# f29h85x_dev_cfg_regs register map
Vendor: Texas Instruments
Peripheral module from a debugger description file (folder HSM).
Registers are 32-bit, read-write, no defined reset value unless marked. A register's access mark holds for its fields unless they carry their own. Offsets are as the file gives them; lines under a group give offsets from that group; [hi:lo] are bit positions; {n}, {i} and the like mark numbered series; 'fields as' and 'values as' point back to an identical list; <NAME> marks a mode.

## DEV_CFG_REGS — DEV CFG Registers
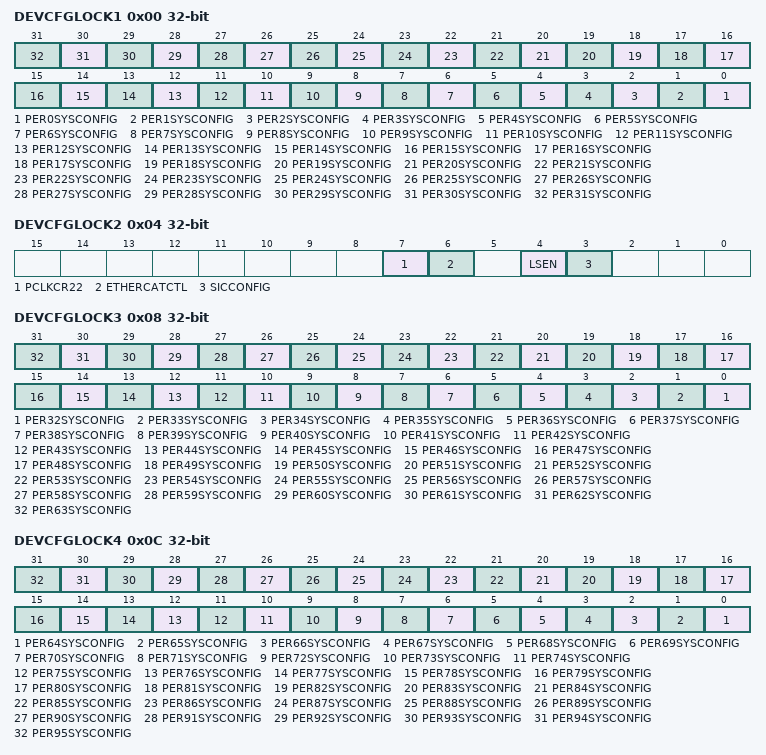
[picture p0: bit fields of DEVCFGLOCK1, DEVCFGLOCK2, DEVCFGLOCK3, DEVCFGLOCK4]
0x00 DEVCFGLOCK1 — Lock bit for PERxSYSCONFIG0-31 registers
  [n] PER{n}SYSCONFIG (n=0..31) — Lock bit for PER{n}SYSCONFIG register
0x04 DEVCFGLOCK2 — Lock bit for DEVCFG registers
  [7] PCLKCR22 — Lock for PCLKCR22
  [6] ETHERCATCTL — Lock for ETHERCATCTL
  [4] LSEN — Lock for LSEN
  [3] SICCONFIG — Lock for SICCONFIG
0x08 DEVCFGLOCK3 — Lock bit for PERxSYSCONFIG32-63 registers
  [n-32] PER{n}SYSCONFIG (n=32..63) — Lock bit for PER{n}SYSCONFIG register
0x0C DEVCFGLOCK4 — Lock bit for PERxSYSCONFIG64-95 registers
  [n-64] PER{n}SYSCONFIG (n=64..95) — Lock bit for PER{n}SYSCONFIG register
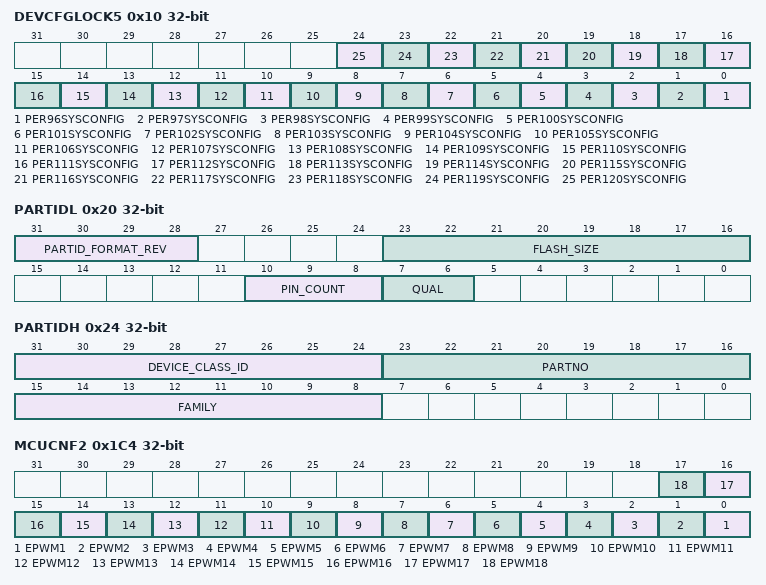
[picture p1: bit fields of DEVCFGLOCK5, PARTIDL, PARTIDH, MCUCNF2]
0x10 DEVCFGLOCK5 — Lock bit for PERxSYSCONFIG96-127 registers
  [n-96] PER{n}SYSCONFIG (n=96..120) — Lock bit for PER{n}SYSCONFIG register
0x14 DEVCFGLOCK6 access not given — Lock bit for PERxSYSCONFIG128-159 registers
0x20 PARTIDL — Lower 32-bit of Device PART Identification Number
  [31:28] PARTID_FORMAT_REV
  [23:16] FLASH_SIZE
  [10:8] PIN_COUNT — Device Pin Count
  [7:6] QUAL — Qualification Status
0x24 PARTIDH access per field — Upper 32-bit of Device PART Identification Number
  [31:24] DEVICE_CLASS_ID ro
  [23:16] PARTNO rw — Device part number
  [15:8] FAMILY rw — Device family
0x28 REVID — Device Revision Number
  [15:0] REVID — Device Revision ID. This is specific to the Device
0x1C0 MCUCNF1 — MCUCNF Capability: EMIF Customization
  [0] EMIF1 — EMIF1 Present
0x1C4 MCUCNF2 — MCUCNF Capability: EPWM
  [n-1] EPWM{n} (n=1..18) — EPWM{n} Present
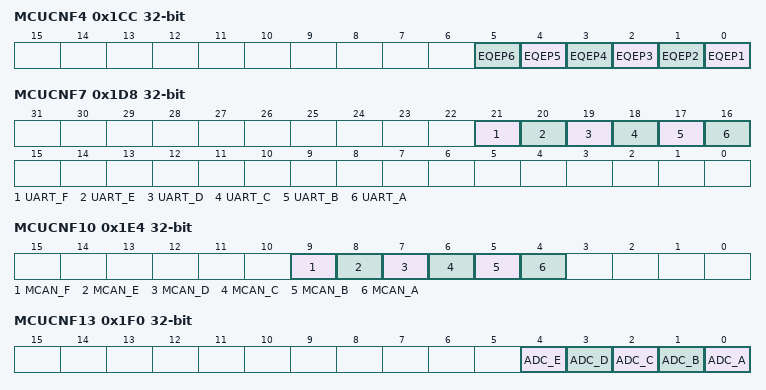
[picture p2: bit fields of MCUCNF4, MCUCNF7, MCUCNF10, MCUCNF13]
0x1CC MCUCNF4 — MCUCNF Capability: EQEP
  [n-1] EQEP{n} (n=1..6) — EQEP{n} Present
0x1D8 MCUCNF7 — MCUCNF Capability: UART
  [21] UART_F — UART_F Present
  [20] UART_E — UART_E Present
  [19] UART_D — UART_D Present
  [18] UART_C — UART_C Present
  [17] UART_B — UART_B Present
  [16] UART_A — UART_A Present
0x1E4 MCUCNF10 — MCUCNF Capability: CAN, MCAN
  [9] MCAN_F — MCAN_F Present
  [8] MCAN_E — MCAN_E Present
  [7] MCAN_D — MCAN_D Present
  [6] MCAN_C — MCAN_C Present
  [5] MCAN_B — MCAN_B Present
  [4] MCAN_A — MCAN_A Present
0x1F0 MCUCNF13 — MCUCNF Capability: AMCUCNF
  [4] ADC_E — ADC_E Present
  [3] ADC_D — ADC_D Present
  [2] ADC_C — ADC_C Present
  [1] ADC_B — ADC_B Present
  [0] ADC_A — ADC_A Present
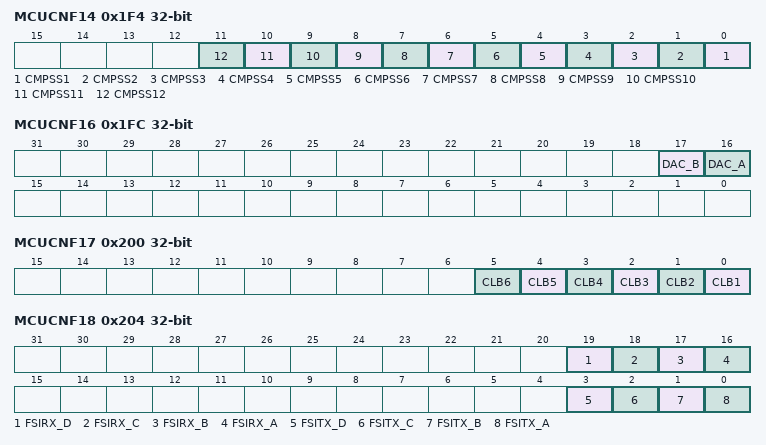
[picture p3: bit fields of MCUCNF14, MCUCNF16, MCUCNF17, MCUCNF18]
0x1F4 MCUCNF14 — MCUCNF Capability: CMPSS
  [n-1] CMPSS{n} (n=1..12) — CMPSS{n} Present
0x1FC MCUCNF16 — MCUCNF Capability: DAC
  [17] DAC_B — DAC_B Present
  [16] DAC_A — DAC_A Present
0x200 MCUCNF17 — MCUCNF Capability: CLB
  [n-1] CLB{n} (n=1..6) — CLB{n} Present
0x204 MCUCNF18 — MCUCNF Capability: FSI
  [19] FSIRX_D — FSIRX_D Present
  [18] FSIRX_C — FSIRX_C Present
  [17] FSIRX_B — FSIRX_B Present
  [16] FSIRX_A — FSIRX_A Present
  [3] FSITX_D — FSITX_D Present
  [2] FSITX_C — FSITX_C Present
  [1] FSITX_B — FSITX_B Present
  [0] FSITX_A — FSITX_A Present
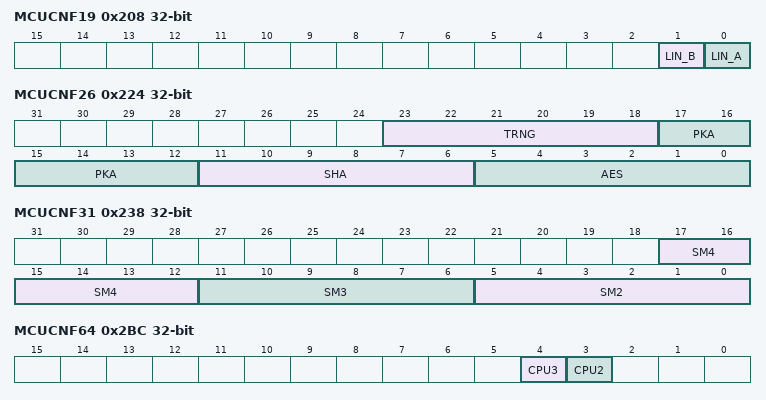
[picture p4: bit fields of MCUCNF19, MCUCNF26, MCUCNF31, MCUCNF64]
0x208 MCUCNF19 — MCUCNF Capability: LIN
  [1] LIN_B — LIN_B Present
  [0] LIN_A — LIN_A Present
0x218 MCUCNF23 — MCUCNF Capability: EtherCAT
  [0] ETHERCAT
0x224 MCUCNF26 — Device Capability: HSM-Crypto Engines AES, SHA, PKA, TRNG
  [23:18] TRNG — TRNG Present
  [17:12] PKA — PKA Present
  [11:6] SHA — SHA Present
  [5:0] AES — AES Present
0x238 MCUCNF31 — Device Capability: HSM-Crypto Engines SM2, SM3, SM4
  [17:12] SM4 — SM4 Present
  [11:6] SM3 — SM3 Present
  [5:0] SM2 — SM2 Present
0x2BC MCUCNF64 — MCUCNF Capability: MCUCNF level, Processing Block, RTDMA Customization
  [4] CPU3 — CPU3SS Present on this device
  [3] CPU2 — CPU2SS Present on this device
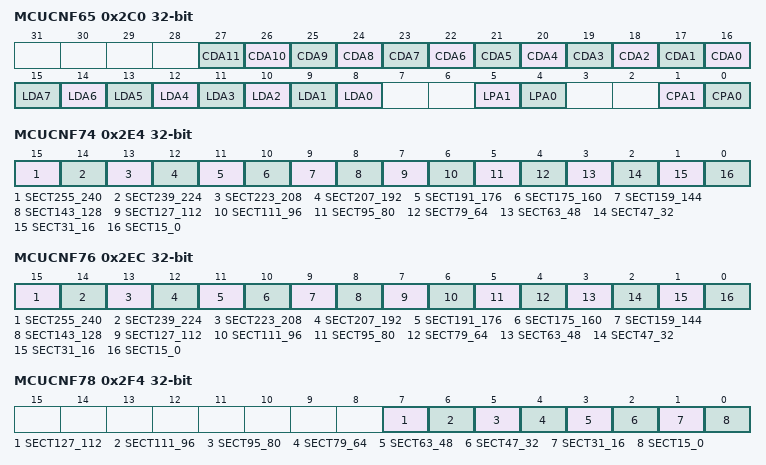
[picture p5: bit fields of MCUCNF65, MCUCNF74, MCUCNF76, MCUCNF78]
0x2C0 MCUCNF65 — MCUCNF Capability: On-chip SRAM Customization
  [n+16] CDA{n} (n=0..11) — CDA{n} Memory Present
  [n+8] LDA{n} (n=0..7) — LDA{n} Memory Present
  [5] LPA1 — LPA1 Memory Present
  [4] LPA0 — LPA0 Memory Present
  [1] CPA1 — CPA1 Memory Present
  [0] CPA0 — CPA0 Memory Present
0x2E4 MCUCNF74 — MCUCNF Capability: FLC1.B0/B1
  [15] SECT255_240 — Flash sectors 255_240 present
  [14] SECT239_224 — Flash sectors 239_224 present
  [13] SECT223_208 — Flash sectors 223_208 present
  [12] SECT207_192 — Flash sectors 207_192 present
  [11] SECT191_176 — Flash sectors 191_176 present
  [10] SECT175_160 — Flash sectors 175_160 present
  [9] SECT159_144 — Flash sectors 159_144 present
  [8] SECT143_128 — Flash sectors 143_128 present
  [7] SECT127_112 — Flash sectors 127_112 present
  [6] SECT111_96 — Flash sectors 111_96 present
  [5] SECT95_80 — Flash sectors 95_80 present
  [4] SECT79_64 — Flash sectors 79_64 present
  [3] SECT63_48 — Flash sectors 63_48 present
  [2] SECT47_32 — Flash sectors 47_32 present
  [1] SECT31_16 — Flash sectors 31_16 present
  [0] SECT15_0 — Flash sectors 15_0 present
0x2EC MCUCNF76 — MCUCNF Capability: FLC1.B2/B3
  fields as MCUCNF74
0x2F4 MCUCNF78 — MCUCNF Capability: FLC1.B4 256KB Data Flash
  [7] SECT127_112 — Flash sectors 127_112 present
  [6] SECT111_96 — Flash sectors 111_96 present
  [5] SECT95_80 — Flash sectors 95_80 present
  [4] SECT79_64 — Flash sectors 79_64 present
  [3] SECT63_48 — Flash sectors 63_48 present
  [2] SECT47_32 — Flash sectors 47_32 present
  [1] SECT31_16 — Flash sectors 31_16 present
  [0] SECT15_0 — Flash sectors 15_0 present
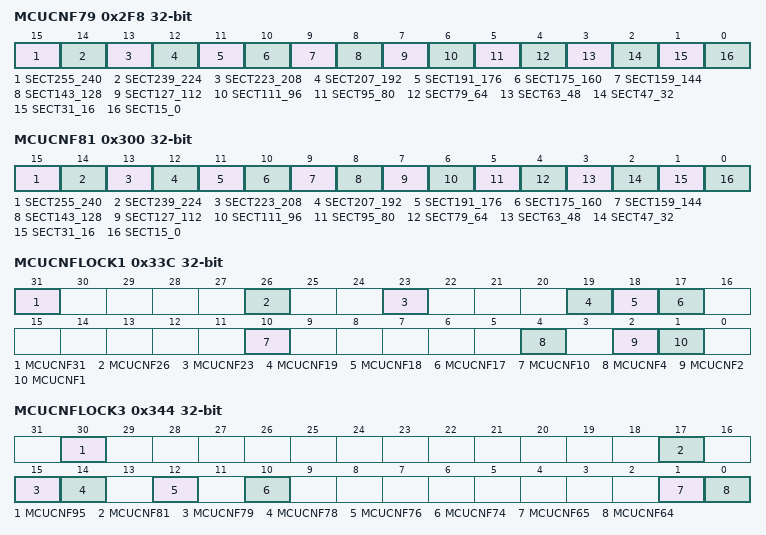
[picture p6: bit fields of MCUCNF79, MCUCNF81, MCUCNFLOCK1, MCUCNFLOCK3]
0x2F8 MCUCNF79 — MCUCNF Capability: FLC2.B0/B1
  fields as MCUCNF74
0x300 MCUCNF81 — MCUCNF Capability: FLC2.B2/B3
  fields as MCUCNF74
0x33C MCUCNFLOCK1 — Lock bit for MCUCNFx registers
  [31] MCUCNF31 — Lock bit for MCUCNF31 register
  [26] MCUCNF26 — Lock bit for MCUCNF26 register
  [23] MCUCNF23 — Lock bit for MCUCNF23 register
  [19] MCUCNF19 — Lock bit for MCUCNF19 register
  [18] MCUCNF18 — Lock bit for MCUCNF18 register
  [17] MCUCNF17 — Lock bit for MCUCNF17 register
  [10] MCUCNF10 — Lock bit for MCUCNF10 register
  [4] MCUCNF4 — Lock bit for MCUCNF4 register
  [2] MCUCNF2 — Lock bit for MCUCNF2 register
  [1] MCUCNF1 — Lock bit for MCUCNF1 register
0x340 MCUCNFLOCK2 access not given — Lock bit for MCUCNFx registers
0x344 MCUCNFLOCK3 — Lock bit for MCUCNFx registers
  [30] MCUCNF95 — Lock bit for MCUCNF95 register
  [17] MCUCNF81 — Lock bit for MCUCNF81 register
  [15] MCUCNF79 — Lock bit for MCUCNF79 register
  [14] MCUCNF78 — Lock bit for MCUCNF78 register
  [12] MCUCNF76 — Lock bit for MCUCNF76 register
  [10] MCUCNF74 — Lock bit for MCUCNF74 register
  [1] MCUCNF65 — Lock bit for MCUCNF65 register
  [0] MCUCNF64 — Lock bit for MCUCNF64 register
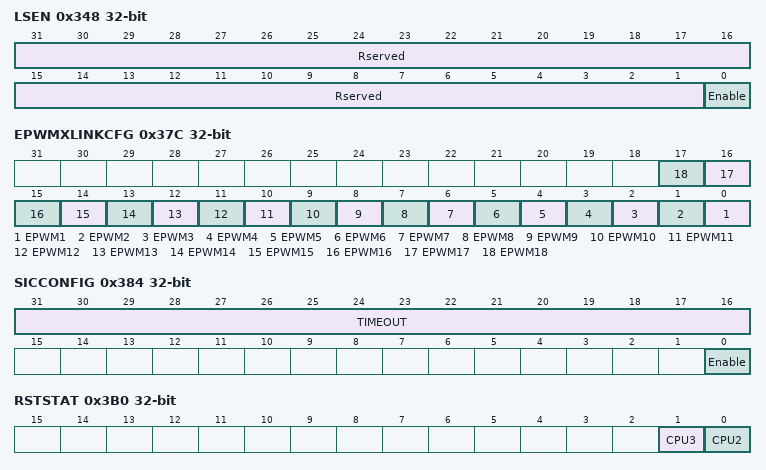
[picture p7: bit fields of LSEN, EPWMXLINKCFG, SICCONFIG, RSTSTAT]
0x348 LSEN access per field — Lockstep enable configuration
  [31:1] Rserved ro — Reserved
  [0] Enable rw — Lockstep Enable
0x37C EPWMXLINKCFG — Confugure which EPWM module instaces are linked in the XLINK scheme
  [n-1] EPWM{n} (n=1..18) — Enable EPWM{n} instance for the XLINK feature
0x384 SICCONFIG — Safety Interconnect(SIC) Configuration - Enable and READY TIMEOUT value
  [31:16] TIMEOUT — Safety Interconnect (SIC) READY TUMEOUT
  [0] Enable — Safety Interconnect Enable
0x3B0 RSTSTAT ro — Reset Status register for secondary CPUs
  [1] CPU3 — CPU3 Reset Status bit
  [0] CPU2 — CPU2 Reset Status bit
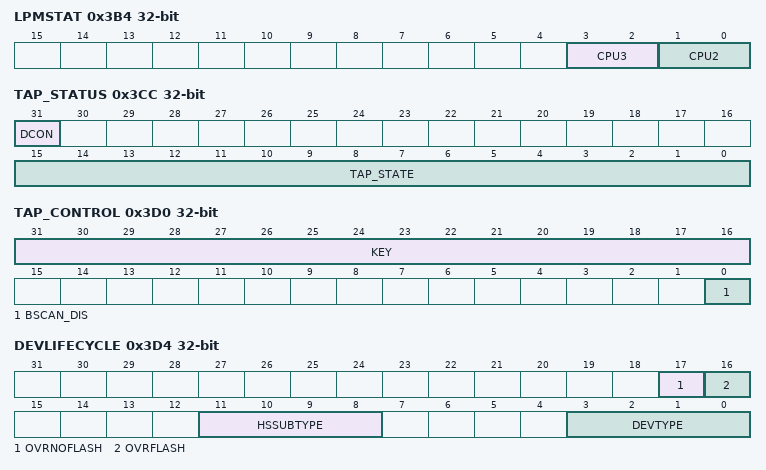
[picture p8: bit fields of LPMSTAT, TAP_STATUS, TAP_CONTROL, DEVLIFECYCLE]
0x3B4 LPMSTAT ro — LPM Status Register for secondary CPUs
  [3:2] CPU3 — CPU3 LPM Status
  [1:0] CPU2 — CPU2 LPM Status
0x3CC TAP_STATUS ro — Status of JTAG State machine and Debugger Connect
  [31] DCON — Debugger Connect Indication
  [15:0] TAP_STATE — Present TAP State
0x3D0 TAP_CONTROL — Disable TAP control
  [31:16] KEY — Key value to enable write
  [0] BSCAN_DIS — Disable BSCAN TAP control
0x3D4 DEVLIFECYCLE ro — Reflect the state of the Device Life Cycle signals reported from the HSM
  [17] OVRNOFLASH — Status of Override mode with no access to Flash
  [16] OVRFLASH — Status of Override mode with access to Flash
  [11:8] HSSUBTYPE — These bits reflect the state from the HSM HS_SUBTYPE
  [3:0] DEVTYPE — These bits reflect the state from HSM DEVICE_TYPE
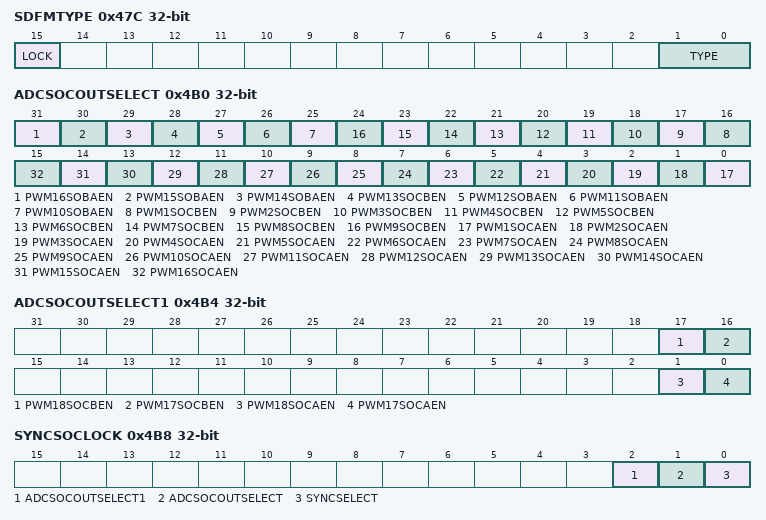
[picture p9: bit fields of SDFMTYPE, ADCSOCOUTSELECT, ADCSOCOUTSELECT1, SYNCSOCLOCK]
0x47C SDFMTYPE — Configures SDFM Type for the device
  [15] LOCK — Lock bit
  [1:0] TYPE — Configure SDFM type
0x4AC SYNCSELECT — Sync Input and Output Select Register
  [28:24] SYNCOUT — Select Syncout Source
0x4B0 ADCSOCOUTSELECT — External ADCSOC Select Register (PWM1-16)
  [31] PWM16SOBAEN — PWM16SOBAEN Enable for ADCSOCBOn
  [30] PWM15SOBAEN — PWM15SOBAEN Enable for ADCSOCBOn
  [29] PWM14SOBAEN — PWM14SOBAEN Enable for ADCSOCBOn
  [28] PWM13SOCBEN — PWM13SOCBEN Enable for ADCSOCBOn
  [27] PWM12SOBAEN — PWM12SOBAEN Enable for ADCSOCBOn
  [26] PWM11SOBAEN — PWM11SOBAEN Enable for ADCSOCBOn
  [25] PWM10SOBAEN — PWM10SOBAEN Enable for ADCSOCBOn
  [n+15] PWM{n}SOCBEN (n=1..9) — PWM{n}SOCBEN Enable for ADCSOCBOn
  [n-1] PWM{n}SOCAEN (n=1..16) — PWM{n}SOCAEN Enable for ADCSOCAOn
0x4B4 ADCSOCOUTSELECT1 — External ADCSOC Select Register (PWM17-32)
  [17] PWM18SOCBEN — PWM18SOCBEN Enable for ADCSOCBOn
  [16] PWM17SOCBEN — PWM17SOCBEN Enable for ADCSOCBOn
  [1] PWM18SOCAEN — PWM18SOCAEN Enable for ADCSOCAOn
  [0] PWM17SOCAEN — PWM17SOCAEN Enable for ADCSOCAOn
0x4B8 SYNCSOCLOCK — SYNCSEL and ADCSOC Select Lock register
  [2] ADCSOCOUTSELECT1 — ADCSOCOUTSELECT1 Register Lock bit
  [1] ADCSOCOUTSELECT — ADCSOCOUTSELECT Register Lock bit
  [0] SYNCSELECT — SYNCSEL Register Lock bit
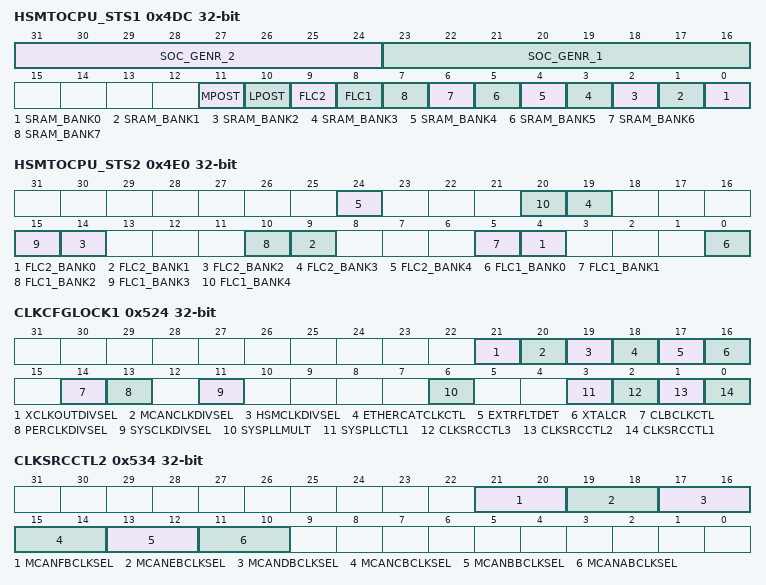
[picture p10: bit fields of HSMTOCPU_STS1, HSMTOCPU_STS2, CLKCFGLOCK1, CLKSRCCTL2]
0x4DC HSMTOCPU_STS1 ro — HSM to C29x Signal Status1
  [31:24] SOC_GENR_2 — HSM to CPU USURP Communication Signal for SOC_GENR_2
  [23:16] SOC_GENR_1 — HSM to CPU USURP Communication Signal for SOC_GENR_1
  [11] MPOST — HSM to CPU USURP Communication Signal for MPOST
  [10] LPOST — HSM to CPU USURP Communication Signal for LPOST
  [9] FLC2 — HSM to CPU USURP Communication Signal for FLC2
  [8] FLC1 — HSM to CPU USURP Communication Signal for FLC1
  [n] SRAM_BANK{n} (n=0..7) — HSM to CPU USURP Communication Signal for SRAM_BANK{n}
0x4E0 HSMTOCPU_STS2 ro — HSM to C29x Signal Status2
  [5n+4] FLC2_BANK{n} (n=0..4) — HSM to CPU USURP Communication Signal for FLC2_BANK{n}
  [5n] FLC1_BANK{n} (n=0..4) — HSM to CPU USURP Communication Signal for FLC1_BANK{n}
{0x4E4+4i} HSM_SECURE_BOOT_INFO_REG{i} ro (i=0..7) — Status information of the secure boot process HSM to CPU1
  [31:0] STATUS — Status information of the secure boot process
{0x504+4i} SOC_SECURE_BOOT_INFO_REG{i} (i=0..7) — Status information of the secure boot process CPU1 to HSM
  [31:0] STATUS — Status information of the secure boot process
0x524 CLKCFGLOCK1 — Lock bit for CLKCFG registers
  [21] XCLKOUTDIVSEL — Lock bit for XCLKOUTDIVSEL register
  [20] MCANCLKDIVSEL — Lock bit for MCANCLKDIVSEL register
  [19] HSMCLKDIVSEL — Lock bit for HSMCLKDIVSEL register
  [18] ETHERCATCLKCTL — Lockbit for ETHERCATCLKCTL register
  [17] EXTRFLTDET — Lockbit for EXTRFLTDET register
  [16] XTALCR — Lock bit for XTALCR and XTALCR2 register
  [14] CLBCLKCTL — Lock bit for CLBCLKCTL register
  [13] PERCLKDIVSEL — Lock bit for PERCLKDIVSEL register
  [11] SYSCLKDIVSEL — Lock bit for SYSCLKDIVSEL register
  [6] SYSPLLMULT — Lock bit for SYSPLLMULT register
  [3] SYSPLLCTL1 — Lock bit for SYSPLLCTL1 register
  [2] CLKSRCCTL3 — Lock bit for CLKSRCCTL3 register
  [1] CLKSRCCTL2 — Lock bit for CLKSRCCTL2 register
  [0] CLKSRCCTL1 — Lock bit for CLKSRCCTL1 register
0x530 CLKSRCCTL1 — Clock Source Control register-1
  [1:0] OSCCLKSRCSEL — OSCCLK Source Select Bit
0x534 CLKSRCCTL2 — Clock Source Control register-2
  [21:20] MCANFBCLKSEL — MCANF Bit Clock Source Select Bit
  [19:18] MCANEBCLKSEL — MCANE Bit Clock Source Select Bit
  [17:16] MCANDBCLKSEL — MCAND Bit Clock Source Select Bit
  [15:14] MCANCBCLKSEL — MCANC Bit Clock Source Select Bit
  [13:12] MCANBBCLKSEL — MCANB Bit Clock Source Select Bit
  [11:10] MCANABCLKSEL — MCANA Bit Clock Source Select Bit
0x538 CLKSRCCTL3 — Clock Source Control register-3
  [4:0] XCLKOUTSEL — XCLKOUT Source Select Bit
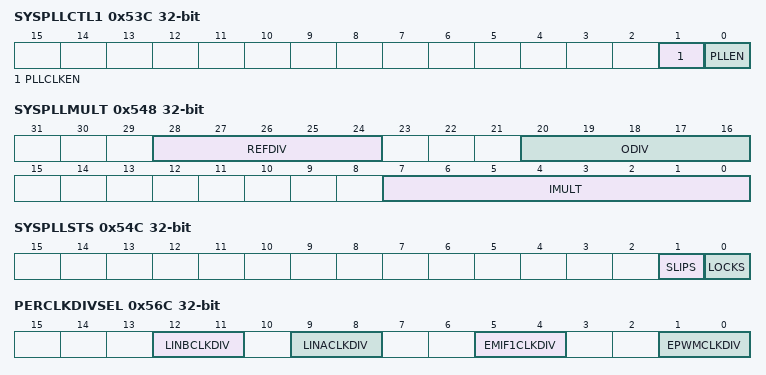
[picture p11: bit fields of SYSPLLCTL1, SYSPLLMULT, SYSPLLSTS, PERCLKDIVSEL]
0x53C SYSPLLCTL1 — SYSPLL Control register-1
  [1] PLLCLKEN — SYSPLL bypassed or included in the PLLSYSCLK path
  [0] PLLEN — SYSPLL enable/disable bit
0x548 SYSPLLMULT — SYSPLL Multiplier register
  [28:24] REFDIV — Reference Clock Divider
  [20:16] ODIV — Output Clock Divider
  [7:0] IMULT — SYSPLL Integer Multiplier
0x54C SYSPLLSTS ro — SYSPLL Status register
  [1] SLIPS — SYSPLL Slip Status Bit
  [0] LOCKS — SYSPLL Lock Status Bit
0x564 SYSCLKDIVSEL — System Clock Divider Select register
  [5:0] PLLSYSCLKDIV — PLLSYSCLK Divide Select
0x56C PERCLKDIVSEL — Peripheral Clock Divider Select register
  [12:11] LINBCLKDIV — LINB Clock Divide Select
  [9:8] LINACLKDIV — LINA Clock Divide Select
  [5:4] EMIF1CLKDIV — EMIF1 Clock Divide Select
  [1:0] EPWMCLKDIV — EPWM Clock Divide Select
0x570 XCLKOUTDIVSEL — XCLKOUT Divider Select register
  [1:0] XCLKOUTDIV — XCLKOUT Divide Select
0x574 HSMCLKDIVSEL — HSM SYSCLK Divider Select register
  [4:0] HSMCLKDIV — Divider value for HSMSYSCLK clock input to HSM
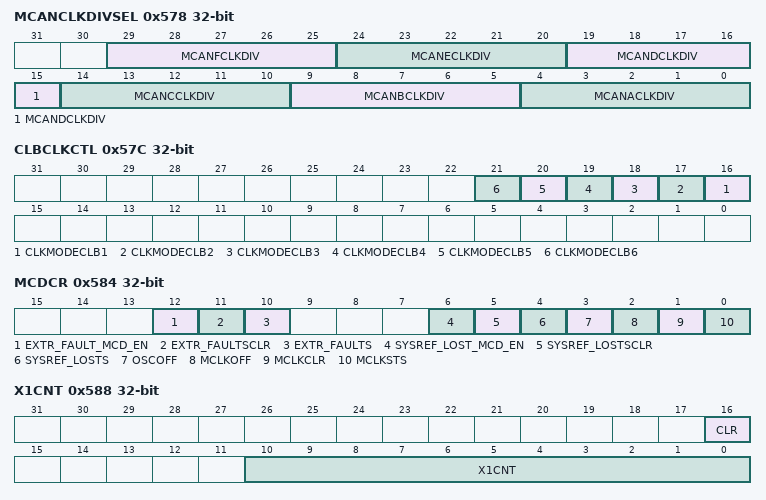
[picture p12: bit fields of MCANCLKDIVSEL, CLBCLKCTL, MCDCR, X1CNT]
0x578 MCANCLKDIVSEL — MCAN Bit Clock Divider Select register
  [29:25] MCANFCLKDIV — Divider CANFD Bit CLK for MCANF
  [24:20] MCANECLKDIV — Divider CANFD Bit CLK for MCANE
  [19:15] MCANDCLKDIV — Divider CANFD Bit CLK for MCAND
  [14:10] MCANCCLKDIV — Divider CANFD Bit CLK for MCANC
  [9:5] MCANBCLKDIV — Divider CANFD Bit CLK for MCANB
  [4:0] MCANACLKDIV — Divider CANFD Bit CLK for MCANA
0x57C CLBCLKCTL — CLB Clocking Control Register
  [n+15] CLKMODECLB{n} (n=1..6) — Clock mode of CLB{n}
0x584 MCDCR access per field — Missing Clock Detect Control Register
  [12] EXTR_FAULT_MCD_EN rw — Configuration to enable EXTR_FAULTS as MCD cause
  [11] EXTR_FAULTSCLR rw — External Resistor fault status clear
  [10] EXTR_FAULTS ro — External Resistor fault indication
  [6] SYSREF_LOST_MCD_EN rw — Enable for PLL REF_CLK_LOST as MCD cause
  [5] SYSREF_LOSTSCLR rw — Clear for Ref clock lost status
  [4] SYSREF_LOSTS ro — SYSPLL Reference Lost Status Bit
  [3] OSCOFF rw — Oscillator Clock Off Bit
  [2] MCLKOFF rw — Missing Clock Detect Off Bit
  [1] MCLKCLR rw — Missing Clock Clear Bit
  [0] MCLKSTS ro — Missing Clock Status Bit
0x588 X1CNT access per field — 10-bit Counter on X1 Clock
  [16] CLR rw — X1 Counter Clear
  [10:0] X1CNT ro — X1 Counter
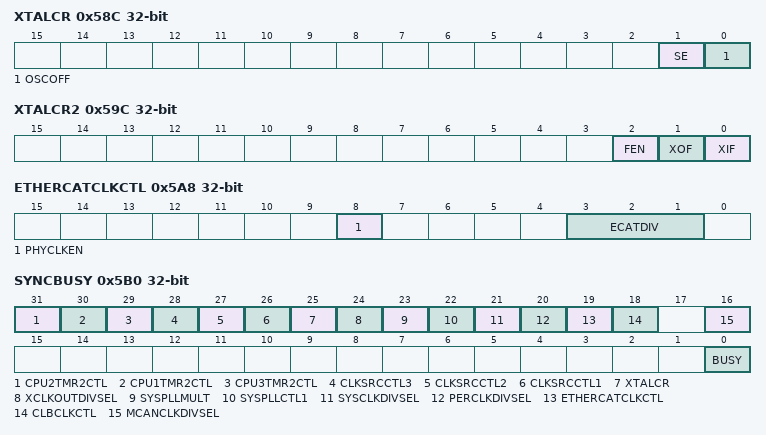
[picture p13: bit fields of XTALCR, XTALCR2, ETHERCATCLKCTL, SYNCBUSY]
0x58C XTALCR — XTAL Control Register
  [1] SE — XTAL Oscilator in Single-Ended mode
  [0] OSCOFF — XTAL Oscillator powered-down
0x59C XTALCR2 — XTAL Control Register for pad init
  [2] FEN — XOSC pads initialisation enable
  [1] XOF — XO Initial value deposited before XOSC start
  [0] XIF — XI Initial value deposited before XOSC start
0x5A8 ETHERCATCLKCTL — EtherCAT Clock Control
  [8] PHYCLKEN — etherCAT PHY clock enable
  [3:1] ECATDIV — etherCAT clock divider configuration.
0x5AC ETHERCATCTL — ETHERCAT control register.
  [0] I2CLOOPBACK — Loopback I2C port of etherCAT IP to I2C_A.
0x5B0 SYNCBUSY ro — Pulse Transfer Sync Busy Status register
  [31] CPU2TMR2CTL — BUSY status bit for CPU2TMR2CTL
  [30] CPU1TMR2CTL — BUSY status bit for CPU1TMR2CTL
  [29] CPU3TMR2CTL — BUSY status bit for CPU3TMR2CTL
  [28] CLKSRCCTL3 — BUSY status bit for CLKSRCCTL3
  [27] CLKSRCCTL2 — BUSY status bit for CLKSRCCTL2
  [26] CLKSRCCTL1 — BUSY status bit for CLKSRCCTL1
  [25] XTALCR — BUSY status bit for XTALCR
  [24] XCLKOUTDIVSEL — BUSY status bit for XCLKOUTDIVSEL
  [23] SYSPLLMULT — BUSY status bit for SYSPLLMULT
  [22] SYSPLLCTL1 — BUSY status bit for SYSPLLCTL1
  [21] SYSCLKDIVSEL — BUSY status bit for SYSCLKDIVSEL
  [20] PERCLKDIVSEL — BUSY status bit for PERCLKDIVSEL
  [19] ETHERCATCLKCTL — BUSY status bit for ETHERCATCLKCTL
  [18] CLBCLKCTL — BUSY status bit for CLBCLKCTL
  [16] MCANCLKDIVSEL — BUSY status bit for MCANCLKDIVSEL
  [0] BUSY — Status bit indicating synchronization in progress
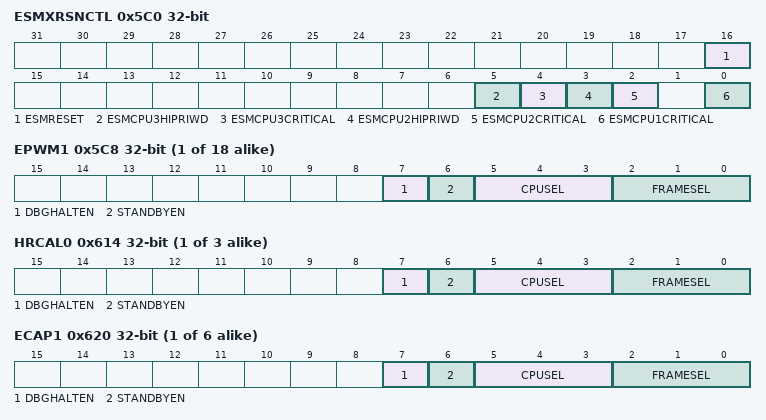
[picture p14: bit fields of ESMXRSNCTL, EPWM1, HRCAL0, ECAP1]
0x5C0 ESMXRSNCTL — Enable ESM reset outputs for XRSn
  [16] ESMRESET — Enable ESMRESET to cause XRSn
  [5] ESMCPU3HIPRIWD — Enable ESMCPU3HIPRIWD to cause XRSn
  [4] ESMCPU3CRITICAL — Enable ESMCPU3CRITICAL to cause XRSn
  [3] ESMCPU2HIPRIWD — Enable ESMCPU2HIPRIWD to cause XRSn
  [2] ESMCPU2CRITICAL — Enable ESMCPU2CRITICAL to cause XRSn
  [0] ESMCPU1CRITICAL — Enable ESMCPU1CRITICAL to cause XRSn
{0x5C4+4i} EPWM{i} (i=1..18) — PER{i+1}SYSCONFIG - Peripheral System Configuration for EPWM{i}
  [7] DBGHALTEN — DBGHALTEN to enable peripheral clock gating based on CPUx
  [6] STANDBYEN — STANDBYEN to enable peripheral clock gating based on CPUx
  [5:3] CPUSEL — CPUSEL Selection for Peripheral Instance
  [2:0] FRAMESEL — FRAMESEL Selection for Peripheral Instance
{0x614+4i} HRCAL{i} (i=0..2) — PER{i+21}SYSCONFIG - Peripheral System Configuration for HRCAL{i}
  fields as EPWM1
{0x61C+4i} ECAP{i} (i=1..6) — PER{i+23}SYSCONFIG - Peripheral System Configuration for ECAP{i}
  fields as EPWM1
{0x634+4i} EQEP{i} (i=1..6) — PER{i+29}SYSCONFIG - Peripheral System Configuration for EQEP{i}
  fields as EPWM1
{0x64C+4i} SDFM{i} (i=1..4) — PER{i+35}SYSCONFIG - Peripheral System Configuration for SDFM{i}
  fields as EPWM1
0x660 UARTA — PER40SYSCONFIG - Peripheral System Configuration for UARTA
  fields as EPWM1
0x664 UARTB — PER41SYSCONFIG - Peripheral System Configuration for UARTB
  fields as EPWM1
0x668 UARTC — PER42SYSCONFIG - Peripheral System Configuration for UARTC
  fields as EPWM1
0x66C UARTD — PER43SYSCONFIG - Peripheral System Configuration for UARTD
  fields as EPWM1
0x670 UARTE — PER44SYSCONFIG - Peripheral System Configuration for UARTE
  fields as EPWM1
0x674 UARTF — PER45SYSCONFIG - Peripheral System Configuration for UARTF
  fields as EPWM1
0x678 SPIA — PER46SYSCONFIG - Peripheral System Configuration for SPIA
  fields as EPWM1
0x67C SPIB — PER47SYSCONFIG - Peripheral System Configuration for SPIB
  fields as EPWM1
0x680 SPIC — PER48SYSCONFIG - Peripheral System Configuration for SPIC
  fields as EPWM1
0x684 SPID — PER49SYSCONFIG - Peripheral System Configuration for SPID
  fields as EPWM1
0x688 SPIE — PER50SYSCONFIG - Peripheral System Configuration for SPIE
  fields as EPWM1
0x68C I2CA — PER51SYSCONFIG - Peripheral System Configuration for I2CA
  fields as EPWM1
0x690 I2CB — PER52SYSCONFIG - Peripheral System Configuration for I2CB
  fields as EPWM1
0x694 PMBUSA — PER53SYSCONFIG - Peripheral System Configuration for PMBUSA
  fields as EPWM1
0x698 LINA — PER54SYSCONFIG - Peripheral System Configuration for LINA
  fields as EPWM1
0x69C LINB — PER55SYSCONFIG - Peripheral System Configuration for LINB
  fields as EPWM1
0x6A0 MCANA — PER56SYSCONFIG - Peripheral System Configuration for MCANA
  fields as EPWM1
0x6A4 MCANB — PER57SYSCONFIG - Peripheral System Configuration for MCANB
  fields as EPWM1
0x6A8 MCANC — PER58SYSCONFIG - Peripheral System Configuration for MCANC
  fields as EPWM1
0x6AC MCAND — PER59SYSCONFIG - Peripheral System Configuration for MCAND
  fields as EPWM1
0x6B0 MCANE — PER60SYSCONFIG - Peripheral System Configuration for MCANE
  fields as EPWM1
0x6B4 MCANF — PER61SYSCONFIG - Peripheral System Configuration for MCANF
  fields as EPWM1
0x6B8 ADCA — PER62SYSCONFIG - Peripheral System Configuration for ADCA
  fields as EPWM1
0x6BC ADCB — PER63SYSCONFIG - Peripheral System Configuration for ADCB
  fields as EPWM1
0x6C0 ADCC — PER64SYSCONFIG - Peripheral System Configuration for ADCC
  fields as EPWM1
0x6C4 ADCD — PER65SYSCONFIG - Peripheral System Configuration for ADCD
  fields as EPWM1
0x6C8 ADCE — PER66SYSCONFIG - Peripheral System Configuration for ADCE
  fields as EPWM1
{0x6C8+4i} CMPSS{i} (i=1..12) — PER{i+66}SYSCONFIG - Peripheral System Configuration for CMPSS{i}
  fields as EPWM1
0x6FC DACA — PER79SYSCONFIG - Peripheral System Configuration for DACA
  fields as EPWM1
0x700 DACB — PER80SYSCONFIG - Peripheral System Configuration for DACB
  fields as EPWM1
{0x700+4i} CLB{i} (i=1..6) — PER{i+80}SYSCONFIG - Peripheral System Configuration for CLB{i}
  fields as EPWM1
0x71C FSITXA — PER87SYSCONFIG - Peripheral System Configuration for FSITXA
  fields as EPWM1
0x720 FSITXB — PER88SYSCONFIG - Peripheral System Configuration for FSITXB
  fields as EPWM1
0x724 FSITXC — PER89SYSCONFIG - Peripheral System Configuration for FSITXC
  fields as EPWM1
0x728 FSITXD — PER90SYSCONFIG - Peripheral System Configuration for FSITXD
  fields as EPWM1
0x72C FSIRXA — PER91SYSCONFIG - Peripheral System Configuration for FSIRXA
  fields as EPWM1
0x730 FSIRXB — PER92SYSCONFIG - Peripheral System Configuration for FSIRXB
  fields as EPWM1
0x734 FSIRXC — PER93SYSCONFIG - Peripheral System Configuration for FSIRXC
  fields as EPWM1
0x738 FSIRXD — PER94SYSCONFIG - Peripheral System Configuration for FSIRXD
  fields as EPWM1
{0x738+4i} DCC{i} (i=1..3) — PER{i+94}SYSCONFIG - Peripheral System Configuration for DCC{i}
  fields as EPWM1
0x748 ETHERCATA — PER98SYSCONFIG - Peripheral System Configuration for ETHERCATA
  fields as EPWM1
0x74C EPG1 — PER99SYSCONFIG - Peripheral System Configuration for EPG1
  fields as EPWM1
{0x74C+4i} SENT{i} (i=1..6) — PER{i+99}SYSCONFIG - Peripheral System Configuration for SENT{i}
  fields as EPWM1
{0x764+4i} ADCCHECKER{i} (i=1..10) — PER{i+105}SYSCONFIG - Peripheral System Configuration for ADCCHECKER{i}
  fields as EPWM1
{0x78C+4i} ADCSEAGGRCPU{i} (i=1..3) — PER{i+115}SYSCONFIG - Peripheral System Configuration for ADCSEAGGRCPU{i}
  fields as EPWM1
0x7A8 RTDMA1CH — PER122SYSCONFIG - Peripheral System Configuration for RTDMA1CH
  fields as EPWM1
0x7AC RTDMA2CH — PER123SYSCONFIG - Peripheral System Configuration for RTDMA2CH
  fields as EPWM1
0x7B0 WADI1 — PER124SYSCONFIG - Peripheral System Configuration for WADI1
  fields as EPWM1
0x7B4 WADI2 — PER125SYSCONFIG - Peripheral System Configuration for WADI2
  fields as EPWM1
0x7B8 INPUTXBARFlags — PER126SYSCONFIG - Peripheral System Configuration for INPUTXBARFlags
  fields as EPWM1
0x7BC OUTPUTXBARFlags — PER127SYSCONFIG - Peripheral System Configuration for OUTPUTXBARFlags
  fields as EPWM1
0x7C0 DLTFIFORegs — PER128SYSCONFIG - Peripheral System Configuration for DLTFIFORegs
  fields as EPWM1
0x7C4 ADC_GLOBAL_REGS — PER129SYSCONFIG - Peripheral System Configuration for ADC_GLOBAL_REGS
  fields as EPWM1
0x7C8 Error_Aggregator — PER130SYSCONFIG - Peripheral System Configuration for Error_Aggregator
  fields as EPWM1
0x7CC ESM — PER131SYSCONFIG - Peripheral System Configuration for ESM ESMCPU1/2/3 and ESMSYS
  fields as EPWM1
0x7E4 PARITY_TEST — Enables parity test
  [3:0] TESTEN — Parity test enable configuration
